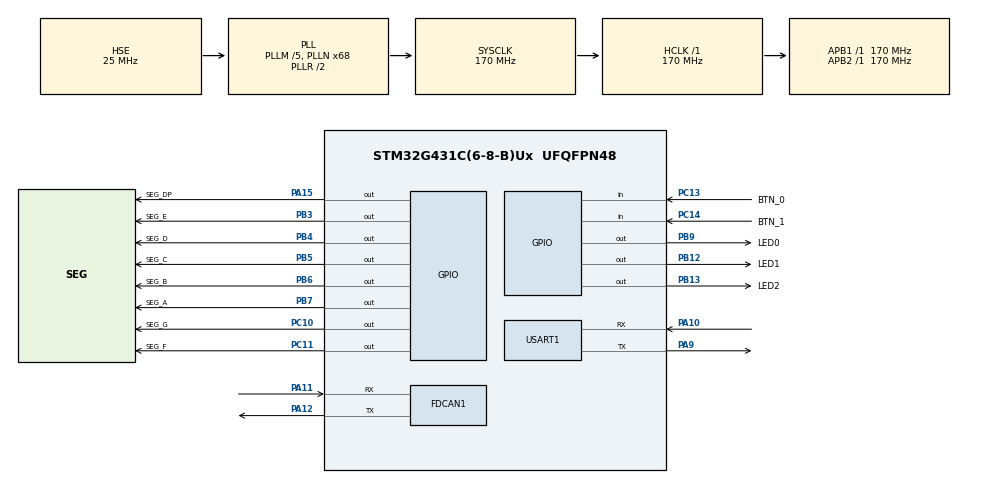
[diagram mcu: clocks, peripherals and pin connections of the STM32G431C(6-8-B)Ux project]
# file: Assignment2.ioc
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Dma.Request0=USART1_RX
Dma.USART1_RX.0.Direction=DMA_PERIPH_TO_MEMORY
Dma.USART1_RX.0.EventEnable=DISABLE
Dma.USART1_RX.0.Instance=DMA1_Channel1
Dma.USART1_RX.0.MemDataAlignment=DMA_MDATAALIGN_BYTE
Dma.USART1_RX.0.MemInc=DMA_MINC_ENABLE
Dma.USART1_RX.0.Mode=DMA_NORMAL
Dma.USART1_RX.0.PeriphDataAlignment=DMA_PDATAALIGN_BYTE
Dma.USART1_RX.0.PeriphInc=DMA_PINC_DISABLE
Dma.USART1_RX.0.Polarity=HAL_DMAMUX_REQ_GEN_RISING
Dma.USART1_RX.0.Priority=DMA_PRIORITY_LOW
Dma.USART1_RX.0.RequestNumber=1
Dma.USART1_RX.0.SignalID=NONE
Dma.USART1_RX.0.SyncEnable=DISABLE
Dma.USART1_RX.0.SyncPolarity=HAL_DMAMUX_SYNC_NO_EVENT
Dma.USART1_RX.0.SyncRequestNumber=1
Dma.USART1_RX.0.SyncSignalID=NONE
FDCAN1.CalculateBaudRateNominal=1000000
FDCAN1.CalculateTimeBitNominal=1000
FDCAN1.CalculateTimeQuantumNominal=100.0
FDCAN1.DataPrescaler=17
FDCAN1.DataTimeSeg1=6
FDCAN1.DataTimeSeg2=3
FDCAN1.ExtFiltersNbr=8
FDCAN1.NominalPrescaler=17
FDCAN1.NominalTimeSeg1=6
FDCAN1.NominalTimeSeg2=3
FDCAN1.StdFiltersNbr=8
Mcu.Family=STM32G4
Mcu.Name=STM32G431C(6-8-B)Ux
Mcu.Package=UFQFPN48
NVIC.DMA1_Channel1_IRQn=true\:0\:0\:false\:false\:true\:false\:true\:true
NVIC.FDCAN1_IT0_IRQn=true\:0\:0\:false\:false\:true\:true\:true\:true
NVIC.FDCAN1_IT1_IRQn=true\:0\:0\:false\:false\:true\:true\:true\:true
NVIC.PriorityGroup=NVIC_PRIORITYGROUP_4
NVIC.USART1_IRQn=true\:0\:0\:false\:false\:true\:true\:true\:true
PA10.Mode=Asynchronous
PA10.Signal=USART1_RX
PA11.Mode=FDCAN_Activate
PA11.Signal=FDCAN1_RX
PA12.Mode=FDCAN_Activate
PA12.Signal=FDCAN1_TX
PA13.Mode=Serial_Wire
PA13.Signal=SYS_JTMS-SWDIO
PA14.Mode=Serial_Wire
PA14.Signal=SYS_JTCK-SWCLK
PA15.GPIO_Label=SEG_DP
PA15.Signal=GPIO_Output
PA9.Mode=Asynchronous
PA9.Signal=USART1_TX
PB12.GPIO_Label=LED1
PB12.Signal=GPIO_Output
PB13.GPIO_Label=LED2
PB13.Signal=GPIO_Output
PB3.GPIO_Label=SEG_E
PB3.Signal=GPIO_Output
PB4.GPIO_Label=SEG_D
PB4.Signal=GPIO_Output
PB5.GPIO_Label=SEG_C
PB5.Signal=GPIO_Output
PB6.GPIO_Label=SEG_B
PB6.Signal=GPIO_Output
PB7.GPIO_Label=SEG_A
PB7.Signal=GPIO_Output
PB9.GPIO_Label=LED0
PB9.Signal=GPIO_Output
PC10.GPIO_Label=SEG_G
PC10.Signal=GPIO_Output
PC11.GPIO_Label=SEG_F
PC11.Signal=GPIO_Output
PC13.GPIO_Label=BTN_0
PC13.Signal=GPIO_Input
PC14-OSC32_IN.GPIO_Label=BTN_1
PC14-OSC32_IN.Signal=GPIO_Input
PF0-OSC_IN.Mode=HSE-External-Oscillator
PF0-OSC_IN.Signal=RCC_OSC_IN
PF1-OSC_OUT.Mode=HSE-External-Oscillator
PF1-OSC_OUT.Signal=RCC_OSC_OUT
ProjectManager.HeapSize=0x200
ProjectManager.StackSize=0x400
ProjectManager.TargetToolchain=Makefile
RCC.ADC12Freq_Value=170000000
RCC.AHBFreq_Value=170000000
RCC.APB1Freq_Value=170000000
RCC.APB1TimFreq_Value=170000000
RCC.APB2Freq_Value=170000000
RCC.APB2TimFreq_Value=170000000
RCC.CortexFreq_Value=170000000
RCC.EXTERNAL_CLOCK_VALUE=12288000
RCC.HCLKFreq_Value=170000000
RCC.HSE_VALUE=25000000
RCC.HSI48_VALUE=48000000
RCC.HSI_VALUE=16000000
RCC.LSE_VALUE=32768
RCC.PLLM=RCC_PLLM_DIV5
RCC.PLLN=68
RCC.PLLSourceVirtual=RCC_PLLSOURCE_HSE
RCC.SYSCLKFreq_VALUE=170000000
RCC.SYSCLKSource=RCC_SYSCLKSOURCE_PLLCLK
RCC.USBFreq_Value=170000000
RCC.VCOOutputFreq_Value=340000000
USART1.VirtualMode-Asynchronous=VM_ASYNC
VP_SYS_VS_DBSignals.Mode=DisableDeadBatterySignals
board=custom

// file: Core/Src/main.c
/* USER CODE BEGIN Header */
/**
 ******************************************************************************
 * @file           : main.c
 * @brief          : Main program body
 ******************************************************************************
 * @attention
 *
 * Copyright (c) 2024 STMicroelectronics.
 * All rights reserved.
 *
 * This software is licensed under terms that can be found in the LICENSE file
 * in the root directory of this software component.
 * If no LICENSE file comes with this software, it is provided AS-IS.
 *
 ******************************************************************************
 */
/* USER CODE END Header */
#include "main.h"
#include "dma.h"
#include "fdcan.h"
#include "usart.h"
#include "gpio.h"

void SystemClock_Config(void);

int main(void)
{

  /* MCU Configuration--------------------------------------------------------*/

  /* Reset of all peripherals, Initializes the Flash interface and the Systick. */
  HAL_Init();

  /* Configure the system clock */
  SystemClock_Config();

  /* Initialize all configured peripherals */
  MX_GPIO_Init();
  MX_DMA_Init();
  MX_USART1_UART_Init();
  MX_FDCAN1_Init();
  /* USER CODE BEGIN 2 */
  extern void mainTask(void);
  mainTask();
  /* USER CODE END 2 */

  /* Infinite loop */
  /* USER CODE BEGIN WHILE */
  // ================================================================ //
  //             Your codes will never reach this point               //
  // ================================================================ //
  while (1) {
    /* USER CODE END WHILE */

    /* USER CODE BEGIN 3 */
    HAL_Delay(1);
  }
  /* USER CODE END 3 */
}

void SystemClock_Config(void)
{
  RCC_OscInitTypeDef RCC_OscInitStruct = {0};
  RCC_ClkInitTypeDef RCC_ClkInitStruct = {0};

  /** Configure the main internal regulator output voltage
  */
  HAL_PWREx_ControlVoltageScaling(PWR_REGULATOR_VOLTAGE_SCALE1_BOOST);

  /** Initializes the RCC Oscillators according to the specified parameters
  * in the RCC_OscInitTypeDef structure.
  */
  RCC_OscInitStruct.OscillatorType = RCC_OSCILLATORTYPE_HSE;
  RCC_OscInitStruct.HSEState = RCC_HSE_ON;
  RCC_OscInitStruct.PLL.PLLState = RCC_PLL_ON;
  RCC_OscInitStruct.PLL.PLLSource = RCC_PLLSOURCE_HSE;
  RCC_OscInitStruct.PLL.PLLM = RCC_PLLM_DIV5;
  RCC_OscInitStruct.PLL.PLLN = 68;
  RCC_OscInitStruct.PLL.PLLP = RCC_PLLP_DIV2;
  RCC_OscInitStruct.PLL.PLLQ = RCC_PLLQ_DIV2;
  RCC_OscInitStruct.PLL.PLLR = RCC_PLLR_DIV2;
  if (HAL_RCC_OscConfig(&RCC_OscInitStruct) != HAL_OK)
  {
    Error_Handler();
  }

  /** Initializes the CPU, AHB and APB buses clocks
  */
  RCC_ClkInitStruct.ClockType = RCC_CLOCKTYPE_HCLK|RCC_CLOCKTYPE_SYSCLK
                              |RCC_CLOCKTYPE_PCLK1|RCC_CLOCKTYPE_PCLK2;
  RCC_ClkInitStruct.SYSCLKSource = RCC_SYSCLKSOURCE_PLLCLK;
  RCC_ClkInitStruct.AHBCLKDivider = RCC_SYSCLK_DIV1;
  RCC_ClkInitStruct.APB1CLKDivider = RCC_HCLK_DIV1;
  RCC_ClkInitStruct.APB2CLKDivider = RCC_HCLK_DIV1;

  if (HAL_RCC_ClockConfig(&RCC_ClkInitStruct, FLASH_LATENCY_4) != HAL_OK)
  {
    Error_Handler();
  }
}

void Error_Handler(void)
{
  __disable_irq();
  while (1) {
  }
}
#ifdef USE_FULL_ASSERT
/**
  * @brief  Reports the name of the source file and the source line number
  *         where the assert_param error has occurred.
  * @param  file: pointer to the source file name
  * @param  line: assert_param error line source number
  * @retval None
  */
void assert_failed(uint8_t *file, uint32_t line)
{
  /* USER CODE BEGIN 6 */
  /* User can add his own implementation to report the file name and line
     number, ex: printf("Wrong parameters value: file %s on line %d\r\n", file,
     line) */
  /* USER CODE END 6 */
}
#endif /* USE_FULL_ASSERT */
